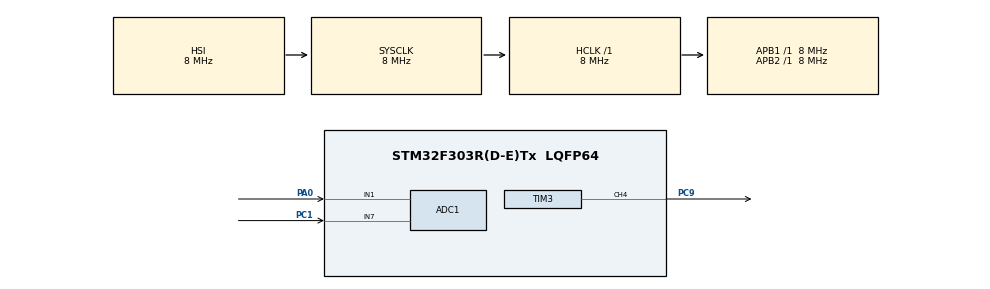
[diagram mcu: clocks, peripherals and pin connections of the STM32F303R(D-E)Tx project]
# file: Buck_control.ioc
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ADC1.Channel-0\#ChannelRegularConversion=ADC_CHANNEL_1
ADC1.Channel-1\#ChannelRegularConversion=ADC_CHANNEL_7
ADC1.ContinuousConvMode=DISABLE
ADC1.DMAContinuousRequests=ENABLE
ADC1.ExternalTrigConv=ADC_EXTERNALTRIGCONV_T15_TRGO
ADC1.NbrOfConversion=2
ADC1.NbrOfConversionFlag=1
ADC1.Offset-0\#ChannelRegularConversion=0
ADC1.Offset-1\#ChannelRegularConversion=0
ADC1.OffsetNumber-0\#ChannelRegularConversion=ADC_OFFSET_NONE
ADC1.OffsetNumber-1\#ChannelRegularConversion=ADC_OFFSET_NONE
ADC1.Rank-0\#ChannelRegularConversion=1
ADC1.Rank-1\#ChannelRegularConversion=2
ADC1.SamplingTime-0\#ChannelRegularConversion=ADC_SAMPLETIME_7CYCLES_5
ADC1.SamplingTime-1\#ChannelRegularConversion=ADC_SAMPLETIME_7CYCLES_5
ADC1.master=1
Dma.ADC1.0.Direction=DMA_PERIPH_TO_MEMORY
Dma.ADC1.0.Instance=DMA1_Channel1
Dma.ADC1.0.MemDataAlignment=DMA_MDATAALIGN_HALFWORD
Dma.ADC1.0.MemInc=DMA_MINC_ENABLE
Dma.ADC1.0.Mode=DMA_CIRCULAR
Dma.ADC1.0.PeriphDataAlignment=DMA_PDATAALIGN_HALFWORD
Dma.ADC1.0.PeriphInc=DMA_PINC_DISABLE
Dma.ADC1.0.Priority=DMA_PRIORITY_LOW
Dma.Request0=ADC1
Mcu.Family=STM32F3
Mcu.Name=STM32F303R(D-E)Tx
Mcu.Package=LQFP64
NVIC.DMA1_Channel1_IRQn=true\:0\:0\:false\:false\:true\:false\:true\:true
NVIC.PriorityGroup=NVIC_PRIORITYGROUP_4
PA0.Mode=IN1-Single-Ended
PA0.Signal=ADC1_IN1
PC1.Signal=ADCx_IN7
PC9.Signal=S_TIM3_CH4
ProjectManager.HeapSize=0x200
ProjectManager.StackSize=0x400
ProjectManager.TargetToolchain=STM32CubeIDE
RCC.AHBFreq_Value=8000000
RCC.APB1Freq_Value=8000000
RCC.APB2Freq_Value=8000000
RCC.CortexFreq_Value=8000000
RCC.HSE_VALUE=8000000
RCC.HSI_VALUE=8000000
RCC.LSE_VALUE=32768
RCC.SYSCLKFreq_VALUE=8000000
RCC.USBFreq_Value=16000000
SH.ADCx_IN7.0=ADC1_IN7,IN7-Single-Ended
SH.S_TIM3_CH4.0=TIM3_CH4,PWM Generation4 CH4
TIM15.Channel-PWM\ Generation1\ No\ Output=TIM_CHANNEL_1
TIM15.Period=1000
TIM15.Prescaler=8
TIM15.TIM_MasterOutputTrigger=TIM_TRGO_UPDATE
TIM3.Channel-PWM\ Generation4\ CH4=TIM_CHANNEL_4
TIM3.Period=100-1
TIM3.Prescaler=4-1
VP_TIM15_VS_no_output1.Mode=PWM Generation1 No Output
VP_TIM3_VS_ClockSourceINT.Mode=Internal
board=custom

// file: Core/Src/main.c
/* USER CODE BEGIN Header */
/**
  ******************************************************************************
  * @file           : main.c
  * @brief          : Main program body
  ******************************************************************************
  * @attention
  *
  * Copyright (c) 2025 STMicroelectronics.
  * All rights reserved.
  *
  * This software is licensed under terms that can be found in the LICENSE file
  * in the root directory of this software component.
  * If no LICENSE file comes with this software, it is provided AS-IS.
  *
  ******************************************************************************
  */
/* USER CODE END Header */
#include "main.h"

/* USER CODE BEGIN PTD */
typedef struct
{
	float Kp;         // Ganho proporcional
	float Ki;         // Ganho integral
	float Kd;         // Ganho derivativo
	float setpoint;   // Valor desejado
	float integral;   // Acumulador do termo integral
	float prev_error; // Erro anterior
	float output;     // Saída do controlador
    float min_output; // limite mínimo
    float max_output; // limite máximo
}PID;

typedef struct
{
	float Vout;
	float IL;
}Buck_control;
/* USER CODE END PTD */

/* USER CODE BEGIN PD */
#define BUCK_SETPOINT 5
#define VOUT_SCALE 33/4096
#define IL_SCALE 3.3/(4096*0.55)
/* USER CODE END PD */

ADC_HandleTypeDef hadc1;
DMA_HandleTypeDef hdma_adc1;

TIM_HandleTypeDef htim3;
TIM_HandleTypeDef htim15;

/* USER CODE BEGIN PV */
PID Voltage_pid;
PID Current_pid;
Buck_control Buck;
static uint16_t internalAdcRawData[2];
static float dutyCycle;
static float V_ref;
uint8_t en_currentControl = 0;
/* USER CODE END PV */

void SystemClock_Config(void);
static void MX_GPIO_Init(void);
static void MX_DMA_Init(void);
static void MX_ADC1_Init(void);
static void MX_TIM3_Init(void);
static void MX_TIM15_Init(void);
/* USER CODE BEGIN PFP */
float PID_run(PID *pid, float measured_value, float dt);
void PID_Init(PID *pid, float Kp, float Ki, float Kd, float setpoint, float min_output, float max_output);
/* USER CODE END PFP */

int main(void)
{

  /* USER CODE BEGIN 1 */
	PID_Init(&Voltage_pid, 1, 1, 1, 12, 0, 100);
	PID_Init(&Current_pid, 1, 1, 1, 1, 0, 5);
  /* USER CODE END 1 */

  /* MCU Configuration--------------------------------------------------------*/

  /* Reset of all peripherals, Initializes the Flash interface and the Systick. */
  HAL_Init();

  /* Configure the system clock */
  SystemClock_Config();

  /* Initialize all configured peripherals */
  MX_GPIO_Init();
  MX_DMA_Init();
  MX_ADC1_Init();
  MX_TIM3_Init();
  MX_TIM15_Init();
  /* USER CODE BEGIN 2 */

  HAL_TIM_PWM_Start(&htim3, TIM_CHANNEL_4);
  HAL_TIM_PWM_Start(&htim15, TIM_CHANNEL_1);
  HAL_ADC_Start_DMA(&hadc1, (uint32_t*) internalAdcRawData, 2);
  /* USER CODE END 2 */

  /* Infinite loop */
  /* USER CODE BEGIN WHILE */
  while (1)
  {
	  if(en_currentControl == 1){
		  V_ref = PID_run(&Current_pid, Buck.IL, 0.1);
		  Voltage_pid.setpoint = V_ref;
	  }
	  dutyCycle = PID_run(&Voltage_pid, Buck.Vout, 0.1);
	  TIM3->CCR4 = (uint32_t) (htim3.Init.Period * dutyCycle/100);
	  HAL_Delay(100);
    /* USER CODE END WHILE */

  }
}

void SystemClock_Config(void)
{
  RCC_OscInitTypeDef RCC_OscInitStruct = {0};
  RCC_ClkInitTypeDef RCC_ClkInitStruct = {0};
  RCC_PeriphCLKInitTypeDef PeriphClkInit = {0};

  /** Initializes the RCC Oscillators according to the specified parameters
  * in the RCC_OscInitTypeDef structure.
  */
  RCC_OscInitStruct.OscillatorType = RCC_OSCILLATORTYPE_HSI;
  RCC_OscInitStruct.HSIState = RCC_HSI_ON;
  RCC_OscInitStruct.HSICalibrationValue = RCC_HSICALIBRATION_DEFAULT;
  RCC_OscInitStruct.PLL.PLLState = RCC_PLL_ON;
  RCC_OscInitStruct.PLL.PLLSource = RCC_PLLSOURCE_HSI;
  RCC_OscInitStruct.PLL.PLLMUL = RCC_PLL_MUL2;
  RCC_OscInitStruct.PLL.PREDIV = RCC_PREDIV_DIV1;
  if (HAL_RCC_OscConfig(&RCC_OscInitStruct) != HAL_OK)
  {
    Error_Handler();
  }

  /** Initializes the CPU, AHB and APB buses clocks
  */
  RCC_ClkInitStruct.ClockType = RCC_CLOCKTYPE_HCLK|RCC_CLOCKTYPE_SYSCLK
                              |RCC_CLOCKTYPE_PCLK1|RCC_CLOCKTYPE_PCLK2;
  RCC_ClkInitStruct.SYSCLKSource = RCC_SYSCLKSOURCE_HSI;
  RCC_ClkInitStruct.AHBCLKDivider = RCC_SYSCLK_DIV1;
  RCC_ClkInitStruct.APB1CLKDivider = RCC_HCLK_DIV1;
  RCC_ClkInitStruct.APB2CLKDivider = RCC_HCLK_DIV1;

  if (HAL_RCC_ClockConfig(&RCC_ClkInitStruct, FLASH_LATENCY_0) != HAL_OK)
  {
    Error_Handler();
  }
  PeriphClkInit.PeriphClockSelection = RCC_PERIPHCLK_TIM15|RCC_PERIPHCLK_ADC12
                              |RCC_PERIPHCLK_TIM34;
  PeriphClkInit.Adc12ClockSelection = RCC_ADC12PLLCLK_DIV1;
  PeriphClkInit.Tim15ClockSelection = RCC_TIM15CLK_HCLK;
  PeriphClkInit.Tim34ClockSelection = RCC_TIM34CLK_HCLK;
  if (HAL_RCCEx_PeriphCLKConfig(&PeriphClkInit) != HAL_OK)
  {
    Error_Handler();
  }
}

static void MX_ADC1_Init(void)
{

  ADC_MultiModeTypeDef multimode = {0};
  ADC_ChannelConfTypeDef sConfig = {0};

  /** Common config
  */
  hadc1.Instance = ADC1;
  hadc1.Init.ClockPrescaler = ADC_CLOCK_ASYNC_DIV1;
  hadc1.Init.Resolution = ADC_RESOLUTION_12B;
  hadc1.Init.ScanConvMode = ADC_SCAN_ENABLE;
  hadc1.Init.ContinuousConvMode = DISABLE;
  hadc1.Init.DiscontinuousConvMode = DISABLE;
  hadc1.Init.ExternalTrigConvEdge = ADC_EXTERNALTRIGCONVEDGE_RISING;
  hadc1.Init.ExternalTrigConv = ADC_EXTERNALTRIGCONV_T15_TRGO;
  hadc1.Init.DataAlign = ADC_DATAALIGN_RIGHT;
  hadc1.Init.NbrOfConversion = 2;
  hadc1.Init.DMAContinuousRequests = ENABLE;
  hadc1.Init.EOCSelection = ADC_EOC_SINGLE_CONV;
  hadc1.Init.LowPowerAutoWait = DISABLE;
  hadc1.Init.Overrun = ADC_OVR_DATA_OVERWRITTEN;
  if (HAL_ADC_Init(&hadc1) != HAL_OK)
  {
    Error_Handler();
  }

  /** Configure the ADC multi-mode
  */
  multimode.Mode = ADC_MODE_INDEPENDENT;
  if (HAL_ADCEx_MultiModeConfigChannel(&hadc1, &multimode) != HAL_OK)
  {
    Error_Handler();
  }

  /** Configure Regular Channel
  */
  sConfig.Channel = ADC_CHANNEL_1;
  sConfig.Rank = ADC_REGULAR_RANK_1;
  sConfig.SingleDiff = ADC_SINGLE_ENDED;
  sConfig.SamplingTime = ADC_SAMPLETIME_7CYCLES_5;
  sConfig.OffsetNumber = ADC_OFFSET_NONE;
  sConfig.Offset = 0;
  if (HAL_ADC_ConfigChannel(&hadc1, &sConfig) != HAL_OK)
  {
    Error_Handler();
  }

  /** Configure Regular Channel
  */
  sConfig.Channel = ADC_CHANNEL_7;
  sConfig.Rank = ADC_REGULAR_RANK_2;
  if (HAL_ADC_ConfigChannel(&hadc1, &sConfig) != HAL_OK)
  {
    Error_Handler();
  }

}

static void MX_TIM3_Init(void)
{

  TIM_ClockConfigTypeDef sClockSourceConfig = {0};
  TIM_MasterConfigTypeDef sMasterConfig = {0};
  TIM_OC_InitTypeDef sConfigOC = {0};

  htim3.Instance = TIM3;
  htim3.Init.Prescaler = 4-1;
  htim3.Init.CounterMode = TIM_COUNTERMODE_UP;
  htim3.Init.Period = 100-1;
  htim3.Init.ClockDivision = TIM_CLOCKDIVISION_DIV1;
  htim3.Init.AutoReloadPreload = TIM_AUTORELOAD_PRELOAD_DISABLE;
  if (HAL_TIM_Base_Init(&htim3) != HAL_OK)
  {
    Error_Handler();
  }
  sClockSourceConfig.ClockSource = TIM_CLOCKSOURCE_INTERNAL;
  if (HAL_TIM_ConfigClockSource(&htim3, &sClockSourceConfig) != HAL_OK)
  {
    Error_Handler();
  }
  if (HAL_TIM_PWM_Init(&htim3) != HAL_OK)
  {
    Error_Handler();
  }
  sMasterConfig.MasterOutputTrigger = TIM_TRGO_RESET;
  sMasterConfig.MasterSlaveMode = TIM_MASTERSLAVEMODE_DISABLE;
  if (HAL_TIMEx_MasterConfigSynchronization(&htim3, &sMasterConfig) != HAL_OK)
  {
    Error_Handler();
  }
  sConfigOC.OCMode = TIM_OCMODE_PWM1;
  sConfigOC.Pulse = 50;
  sConfigOC.OCPolarity = TIM_OCPOLARITY_HIGH;
  sConfigOC.OCFastMode = TIM_OCFAST_DISABLE;
  if (HAL_TIM_PWM_ConfigChannel(&htim3, &sConfigOC, TIM_CHANNEL_4) != HAL_OK)
  {
    Error_Handler();
  }
  HAL_TIM_MspPostInit(&htim3);

}

static void MX_TIM15_Init(void)
{

  TIM_MasterConfigTypeDef sMasterConfig = {0};
  TIM_OC_InitTypeDef sConfigOC = {0};
  TIM_BreakDeadTimeConfigTypeDef sBreakDeadTimeConfig = {0};

  htim15.Instance = TIM15;
  htim15.Init.Prescaler = 8;
  htim15.Init.CounterMode = TIM_COUNTERMODE_UP;
  htim15.Init.Period = 1000;
  htim15.Init.ClockDivision = TIM_CLOCKDIVISION_DIV1;
  htim15.Init.RepetitionCounter = 0;
  htim15.Init.AutoReloadPreload = TIM_AUTORELOAD_PRELOAD_DISABLE;
  if (HAL_TIM_PWM_Init(&htim15) != HAL_OK)
  {
    Error_Handler();
  }
  sMasterConfig.MasterOutputTrigger = TIM_TRGO_UPDATE;
  sMasterConfig.MasterSlaveMode = TIM_MASTERSLAVEMODE_DISABLE;
  if (HAL_TIMEx_MasterConfigSynchronization(&htim15, &sMasterConfig) != HAL_OK)
  {
    Error_Handler();
  }
  sConfigOC.OCMode = TIM_OCMODE_PWM1;
  sConfigOC.Pulse = 0;
  sConfigOC.OCPolarity = TIM_OCPOLARITY_HIGH;
  sConfigOC.OCNPolarity = TIM_OCNPOLARITY_HIGH;
  sConfigOC.OCFastMode = TIM_OCFAST_DISABLE;
  sConfigOC.OCIdleState = TIM_OCIDLESTATE_RESET;
  sConfigOC.OCNIdleState = TIM_OCNIDLESTATE_RESET;
  if (HAL_TIM_PWM_ConfigChannel(&htim15, &sConfigOC, TIM_CHANNEL_1) != HAL_OK)
  {
    Error_Handler();
  }
  sBreakDeadTimeConfig.OffStateRunMode = TIM_OSSR_DISABLE;
  sBreakDeadTimeConfig.OffStateIDLEMode = TIM_OSSI_DISABLE;
  sBreakDeadTimeConfig.LockLevel = TIM_LOCKLEVEL_OFF;
  sBreakDeadTimeConfig.DeadTime = 0;
  sBreakDeadTimeConfig.BreakState = TIM_BREAK_DISABLE;
  sBreakDeadTimeConfig.BreakPolarity = TIM_BREAKPOLARITY_HIGH;
  sBreakDeadTimeConfig.BreakFilter = 0;
  sBreakDeadTimeConfig.AutomaticOutput = TIM_AUTOMATICOUTPUT_DISABLE;
  if (HAL_TIMEx_ConfigBreakDeadTime(&htim15, &sBreakDeadTimeConfig) != HAL_OK)
  {
    Error_Handler();
  }

}

static void MX_DMA_Init(void)
{

  /* DMA controller clock enable */
  __HAL_RCC_DMA1_CLK_ENABLE();

  /* DMA interrupt init */
  /* DMA1_Channel1_IRQn interrupt configuration */
  HAL_NVIC_SetPriority(DMA1_Channel1_IRQn, 0, 0);
  HAL_NVIC_EnableIRQ(DMA1_Channel1_IRQn);

}

static void MX_GPIO_Init(void)
{

  /* GPIO Ports Clock Enable */
  __HAL_RCC_GPIOC_CLK_ENABLE();
  __HAL_RCC_GPIOA_CLK_ENABLE();

}

/* USER CODE BEGIN 4 */
/**
 * @brief Internal ADC Conversion Complete callback
 * @retval None
 */
void HAL_ADC_ConvCpltCallback(ADC_HandleTypeDef *hadc) {
	Buck.Vout = internalAdcRawData[0] * VOUT_SCALE;
	Buck.IL = internalAdcRawData[1] * IL_SCALE;
}

void PID_Init(PID *pid, float Kp, float Ki, float Kd, float setpoint, float min_output, float max_output) {
    pid->Kp = Kp;
    pid->Ki = Ki;
    pid->Kd = Kd;
    pid->setpoint = setpoint;
    pid->integral = 0.0f;
    pid->prev_error = 0.0f;
    pid->output = 0.0f;
    pid->min_output = min_output;
	pid->max_output = max_output;
}

float PID_run(PID *pid, float measured_value, float dt)
{
	float error = pid->setpoint - measured_value;
	pid->integral += error * dt;

	 // Limita integral com base nos limites de saída e ganho Ki
	float max_integral = pid->max_output / (pid->Ki > 0.0f ? pid->Ki : 1.0f);
	float min_integral = pid->min_output / (pid->Ki > 0.0f ? pid->Ki : 1.0f);
	if (pid->integral > max_integral) pid->integral = max_integral;
	if (pid->integral < min_integral) pid->integral = min_integral;

	float derivative = (error - pid->prev_error) / dt;

	pid->output = pid->Kp * error + pid->Ki * pid->integral + pid->Kd * derivative;

	// Limita a saída usando os valores da struct
	if (pid->output > pid->max_output) pid->output = pid->max_output;
	if (pid->output < pid->min_output) pid->output = pid->min_output;

	pid->prev_error = error;

	return pid->output;
}

/* USER CODE END 4 */

void Error_Handler(void)
{
  __disable_irq();
  while (1)
  {
  }
}
